# cc13x2_cc26x2 register map
File version: 2.1
CPU: CM4 r0p1, little endian, MPU, FPU, 3 interrupt priority bits
Registers are 32-bit, read-write, reset 0x0 unless marked. A register's access mark holds for its fields unless they carry their own. Offsets are from the block's base; [hi:lo] are bit positions; {n}, {i} and the like mark numbered series.

## CPU_SCS — Cortex-M's System Control Space (SCS)
Base 0xE000E000
0x04 ICTR ro reset 0x1 — Interrupt Control Type ead this register to see the number of interrupt lines that the NVIC supports.
  [2:0] INTLINESNUM
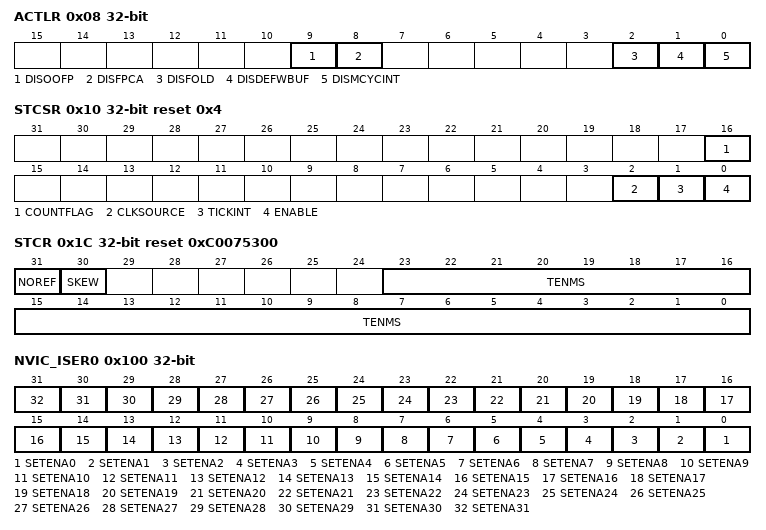
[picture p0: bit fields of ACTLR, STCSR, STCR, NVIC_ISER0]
0x08 ACTLR — Auxiliary Control his register is used to disable certain aspects of functionality within the processor
  [9] DISOOFP, [8] DISFPCA, [2] DISFOLD, [1] DISDEFWBUF, [0] DISMCYCINT
0x10 STCSR reset 0x4 — SysTick Control and Status his register enables the SysTick features and returns status flags related to SysTick.
  [16] COUNTFLAG, [2] CLKSOURCE, [1] TICKINT, [0] ENABLE
0x14 STRVR — SysTick Reload Value his register is used to specify the start value to load into the current value register STCVR.CURRENT when the counter reaches 0. It can be any value between 1 and 0x00FFFFFF. A start value of 0 is possible, but has no effect because the SysTick interrupt and STCSR.COUNTFLAG are activated when counting from 1 to 0.
  [23:0] RELOAD
0x18 STCVR — SysTick Current Value ead from this register returns the current value of SysTick counter. Writing to this register resets the SysTick counter (as well as STCSR.COUNTFLAG).
  [23:0] CURRENT
0x1C STCR ro reset 0xC0075300 — SysTick Calibration Value sed to enable software to scale to any required speed using divide and multiply.
  [31] NOREF, [30] SKEW, [23:0] TENMS
0x100 NVIC_ISER0 — Irq 0 to 31 Set Enable his register is used to enable interrupts and determine which interrupts are currently enabled.
  [n] SETENA{n} (n=0..31)
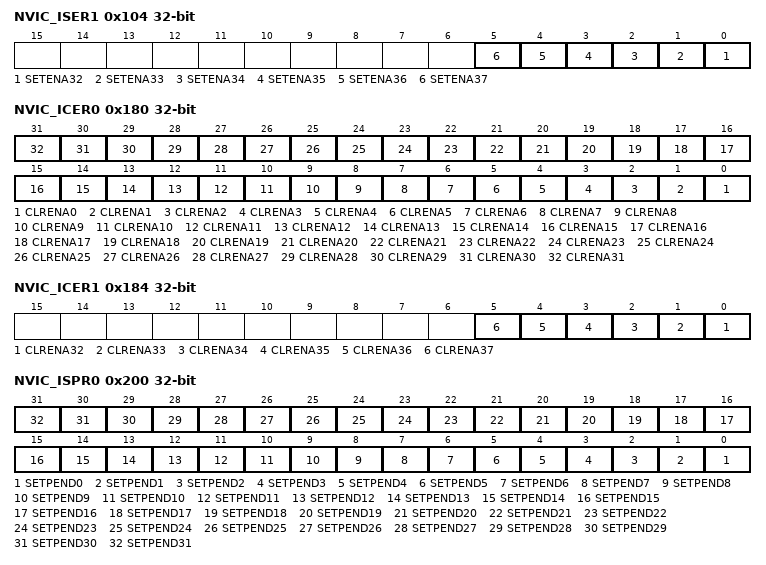
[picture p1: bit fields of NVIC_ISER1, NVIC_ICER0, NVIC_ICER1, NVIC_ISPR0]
0x104 NVIC_ISER1 — Irq 32 to 63 Set Enable his register is used to enable interrupts and determine which interrupts are currently enabled.
  [n-32] SETENA{n} (n=32..37)
0x180 NVIC_ICER0 — Irq 0 to 31 Clear Enable his register is used to disable interrupts and determine which interrupts are currently enabled.
  [n] CLRENA{n} (n=0..31)
0x184 NVIC_ICER1 — Irq 32 to 63 Clear Enable his register is used to disable interrupts and determine which interrupts are currently enabled.
  [n-32] CLRENA{n} (n=32..37)
0x200 NVIC_ISPR0 — Irq 0 to 31 Set Pending his register is used to force interrupts into the pending state and determine which interrupts are currently pending.
  [n] SETPEND{n} (n=0..31)
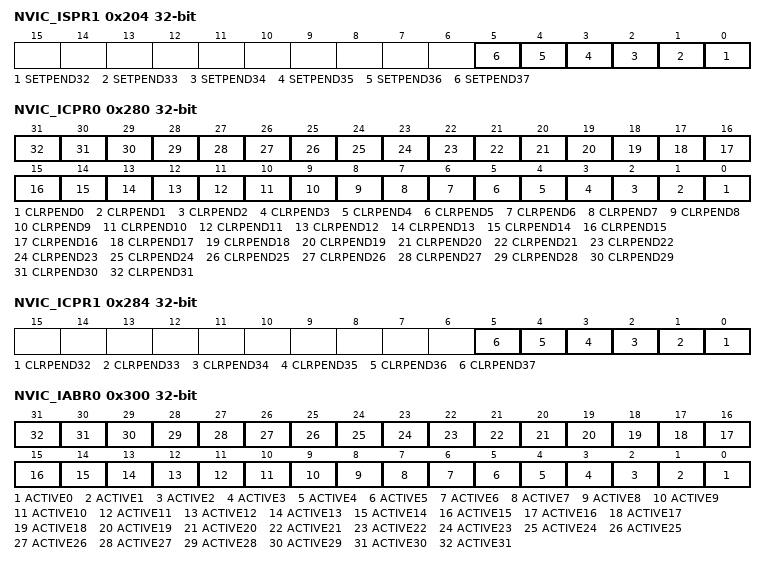
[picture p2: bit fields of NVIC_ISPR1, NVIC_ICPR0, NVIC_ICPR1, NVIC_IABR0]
0x204 NVIC_ISPR1 — Irq 32 to 63 Set Pending his register is used to force interrupts into the pending state and determine which interrupts are currently pending.
  [n-32] SETPEND{n} (n=32..37)
0x280 NVIC_ICPR0 — Irq 0 to 31 Clear Pending his register is used to clear pending interrupts and determine which interrupts are currently pending.
  [n] CLRPEND{n} (n=0..31)
0x284 NVIC_ICPR1 — Irq 32 to 63 Clear Pending his register is used to clear pending interrupts and determine which interrupts are currently pending.
  [n-32] CLRPEND{n} (n=32..37)
0x300 NVIC_IABR0 ro — Irq 0 to 31 Active Bit his register is used to determine which interrupts are active. Each flag in the register corresponds to one interrupt.
  [n] ACTIVE{n} (n=0..31)
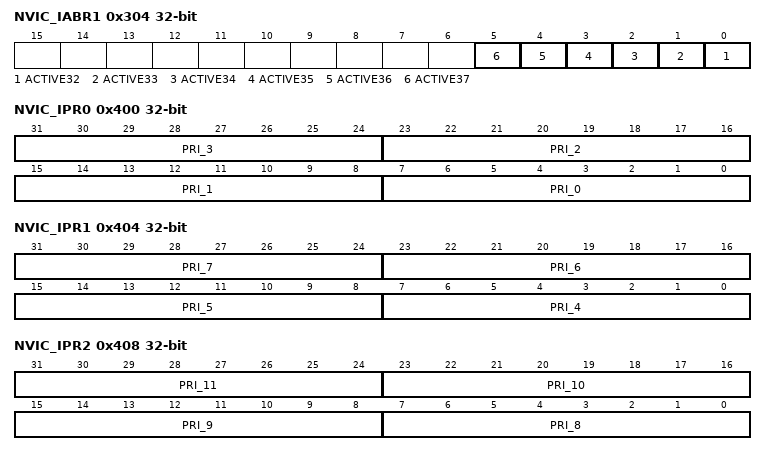
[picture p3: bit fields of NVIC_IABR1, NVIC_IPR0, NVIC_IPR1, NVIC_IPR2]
0x304 NVIC_IABR1 ro — Irq 32 to 63 Active Bit his register is used to determine which interrupts are active. Each flag in the register corresponds to one interrupt.
  [n-32] ACTIVE{n} (n=32..37)
0x400 NVIC_IPR0 — Irq 0 to 3 Priority his register is used to assign a priority from 0 to 255 to each of the available interrupts. 0 is the highest priority, and 255 is the lowest. The interpretation of the Interrupt Priority Registers changes based on the setting in AIRCR.PRIGROUP.
  [8n+7:8n] PRI_{n} (n=0..3)
0x404 NVIC_IPR1 — Irq 4 to 7 Priority his register is used to assign a priority from 0 to 255 to each of the available interrupts. 0 is the highest priority, and 255 is the lowest. The interpretation of the Interrupt Priority Registers changes based on the setting in AIRCR.PRIGROUP.
  [8n-25:8n-32] PRI_{n} (n=4..7)
0x408 NVIC_IPR2 — Irq 8 to 11 Priority his register is used to assign a priority from 0 to 255 to each of the available interrupts. 0 is the highest priority, and 255 is the lowest. The interpretation of the Interrupt Priority Registers changes based on the setting in AIRCR.PRIGROUP.
  [8n-57:8n-64] PRI_{n} (n=8..11)
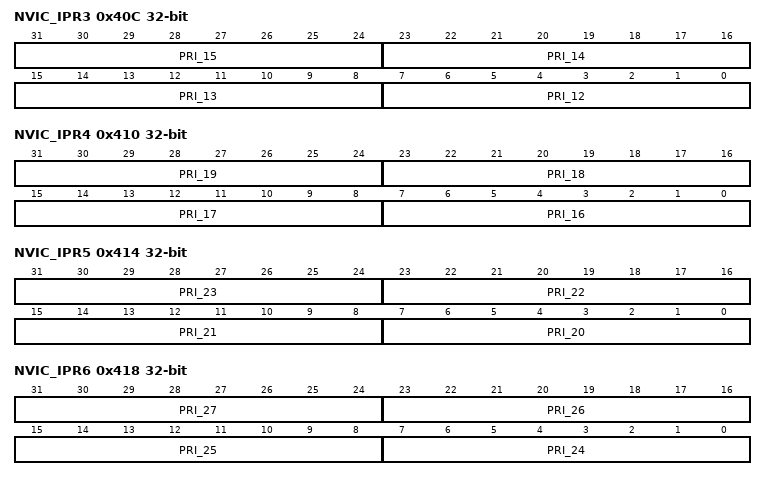
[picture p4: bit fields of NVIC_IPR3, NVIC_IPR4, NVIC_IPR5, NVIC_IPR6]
0x40C NVIC_IPR3 — Irq 12 to 15 Priority his register is used to assign a priority from 0 to 255 to each of the available interrupts. 0 is the highest priority, and 255 is the lowest. The interpretation of the Interrupt Priority Registers changes based on the setting in AIRCR.PRIGROUP.
  [8n-89:8n-96] PRI_{n} (n=12..15)
0x410 NVIC_IPR4 — Irq 16 to 19 Priority his register is used to assign a priority from 0 to 255 to each of the available interrupts. 0 is the highest priority, and 255 is the lowest. The interpretation of the Interrupt Priority Registers changes based on the setting in AIRCR.PRIGROUP.
  [8n-121:8n-128] PRI_{n} (n=16..19)
0x414 NVIC_IPR5 — Irq 20 to 23 Priority his register is used to assign a priority from 0 to 255 to each of the available interrupts. 0 is the highest priority, and 255 is the lowest. The interpretation of the Interrupt Priority Registers changes based on the setting in AIRCR.PRIGROUP.
  [8n-153:8n-160] PRI_{n} (n=20..23)
0x418 NVIC_IPR6 — Irq 24 to 27 Priority his register is used to assign a priority from 0 to 255 to each of the available interrupts. 0 is the highest priority, and 255 is the lowest. The interpretation of the Interrupt Priority Registers changes based on the setting in AIRCR.PRIGROUP.
  [8n-185:8n-192] PRI_{n} (n=24..27)
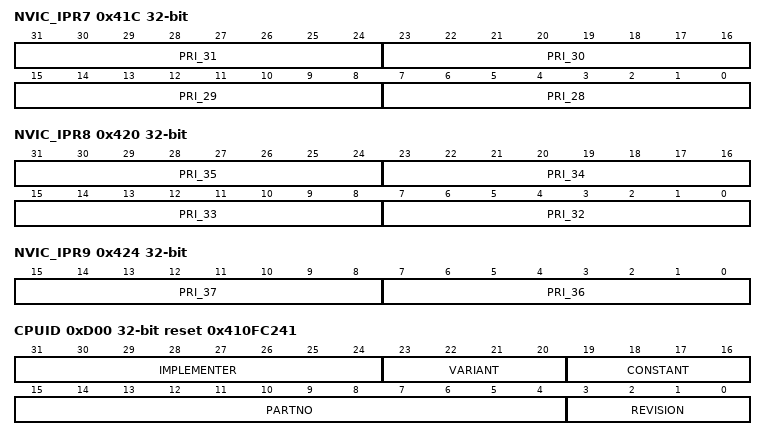
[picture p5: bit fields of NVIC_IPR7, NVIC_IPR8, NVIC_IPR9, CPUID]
0x41C NVIC_IPR7 — Irq 28 to 31 Priority his register is used to assign a priority from 0 to 255 to each of the available interrupts. 0 is the highest priority, and 255 is the lowest. The interpretation of the Interrupt Priority Registers changes based on the setting in AIRCR.PRIGROUP.
  [8n-217:8n-224] PRI_{n} (n=28..31)
0x420 NVIC_IPR8 — Irq 32 to 35 Priority his register is used to assign a priority from 0 to 255 to each of the available interrupts. 0 is the highest priority, and 255 is the lowest. The interpretation of the Interrupt Priority Registers changes based on the setting in AIRCR.PRIGROUP.
  [8n-249:8n-256] PRI_{n} (n=32..35)
0x424 NVIC_IPR9 — Irq 32 to 35 Priority his register is used to assign a priority from 0 to 255 to each of the available interrupts. 0 is the highest priority, and 255 is the lowest. The interpretation of the Interrupt Priority Registers changes based on the setting in AIRCR.PRIGROUP.
  [15:8] PRI_37, [7:0] PRI_36
0xD00 CPUID ro reset 0x410FC241 — CPUID Base his register determines the ID number of the processor core, the version number of the processor core and the implementation details of the processor core.
  [31:24] IMPLEMENTER, [23:20] VARIANT, [19:16] CONSTANT, [15:4] PARTNO, [3:0] REVISION
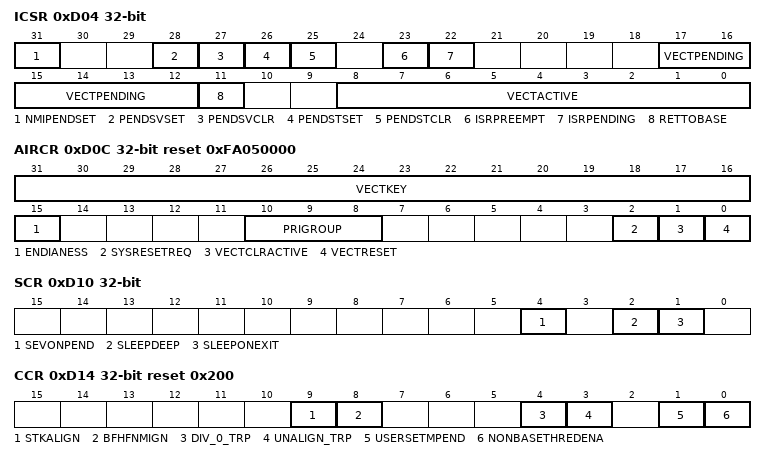
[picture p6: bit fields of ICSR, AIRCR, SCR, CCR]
0xD04 ICSR — Interrupt Control State his register is used to set a pending Non-Maskable Interrupt (NMI), set or clear a pending SVC, set or clear a pending SysTick, check for pending exceptions, check the vector number of the highest priority pended exception, and check the vector number of the active exception.
  [31] NMIPENDSET, [28] PENDSVSET, [27] PENDSVCLR, [26] PENDSTSET, [25] PENDSTCLR, [23] ISRPREEMPT, [22] ISRPENDING, [17:12] VECTPENDING, [11] RETTOBASE, [8:0] VECTACTIVE
0xD08 VTOR — Vector Table Offset his register is used to relocated the vector table base address. The vector table base offset determines the offset from the bottom of the memory map. The two most significant bits and the seven least significant bits of the vector table base offset must be 0. The portion of vector table base offset that is allowed to change is TBLOFF.
  [29:7] TBLOFF
0xD0C AIRCR reset 0xFA050000 — Application Interrupt/Reset Control his register is used to determine data endianness, clear all active state information for debug or to recover from a hard failure, execute a system reset, alter the priority grouping position (binary point).
  [31:16] VECTKEY, [15] ENDIANESS, [10:8] PRIGROUP, [2] SYSRESETREQ, [1] VECTCLRACTIVE, [0] VECTRESET
0xD10 SCR — System Control his register is used for power-management functions, i.e., signaling to the system when the processor can enter a low power state, controlling how the processor enters and exits low power states.
  [4] SEVONPEND, [2] SLEEPDEEP, [1] SLEEPONEXIT
0xD14 CCR reset 0x200 — Configuration Control his register is used to enable NMI, HardFault and FAULTMASK to ignore bus fault, trap divide by zero and unaligned accesses, enable user access to the Software Trigger Interrupt Register (STIR), control entry to Thread Mode.
  [9] STKALIGN, [8] BFHFNMIGN, [4] DIV_0_TRP, [3] UNALIGN_TRP, [1] USERSETMPEND, [0] NONBASETHREDENA
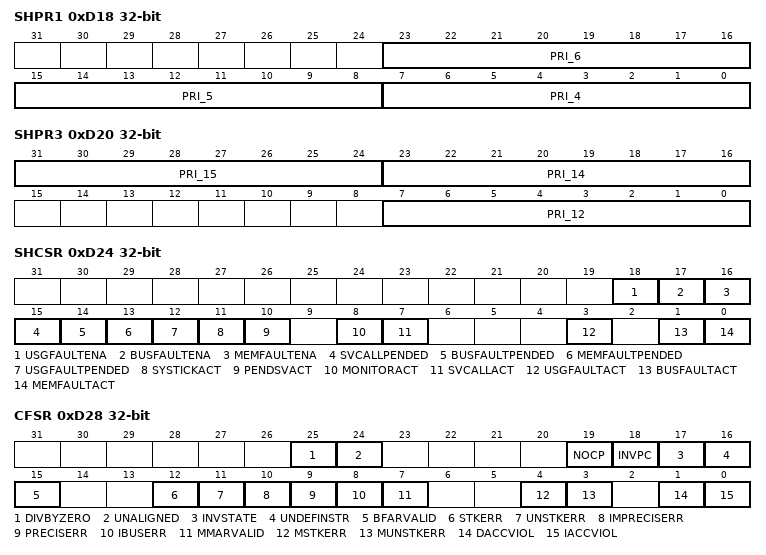
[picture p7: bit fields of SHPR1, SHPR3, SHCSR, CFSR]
0xD18 SHPR1 — System Handlers 4-7 Priority his register is used to prioritize the following system handlers: Memory manage, Bus fault, and Usage fault. System Handlers are a special class of exception handler that can have their priority set to any of the priority levels. Most can be masked on (enabled) or off (disabled). When disabled, the fault is always treated as a Hard Fault.
  [23:16] PRI_6, [15:8] PRI_5, [7:0] PRI_4
0xD1C SHPR2 — System Handlers 8-11 Priority his register is used to prioritize the SVC handler. System Handlers are a special class of exception handler that can have their priority set to any of the priority levels. Most can be masked on (enabled) or off (disabled). When disabled, the fault is always treated as a Hard Fault.
  [31:24] PRI_11
0xD20 SHPR3 — System Handlers 12-15 Priority his register is used to prioritize the following system handlers: SysTick, PendSV and Debug Monitor. System Handlers are a special class of exception handler that can have their priority set to any of the priority levels. Most can be masked on (enabled) or off (disabled). When disabled, the fault is always treated as a Hard Fault.
  [31:24] PRI_15, [23:16] PRI_14, [7:0] PRI_12
0xD24 SHCSR — System Handler Control and State his register is used to enable or disable the system handlers, determine the pending status of bus fault, mem manage fault, and SVC, determine the active status of the system handlers. If a fault condition occurs while its fault handler is disabled, the fault escalates to a Hard Fault.
  [18] USGFAULTENA, [17] BUSFAULTENA, [16] MEMFAULTENA, [15] SVCALLPENDED, [14] BUSFAULTPENDED, [13] MEMFAULTPENDED, [12] USGFAULTPENDED, [11] SYSTICKACT, [10] PENDSVACT, [8] MONITORACT, [7] SVCALLACT, [3] USGFAULTACT, [1] BUSFAULTACT, [0] MEMFAULTACT
0xD28 CFSR — Configurable Fault Status his register is used to obtain information about local faults. These registers include three subsections: The first byte is Memory Manage Fault Status Register (MMFSR). The second byte is Bus Fault Status Register (BFSR). The higher half-word is Usage Fault Status Register (UFSR). The flags in these registers indicate the causes of local faults. Multiple flags can be set if more than one fault occurs. These register are read/write-clear. This means that they can be read normally, but writing a 1 to any bit clears that bit. he CFSR is byte accessible. CFSR or its subregisters can be accessed as follows: he following accesses are possible to the CFSR register: access the complete register with a word access to 0xE000ED28. access the MMFSR with a byte access to 0xE000ED28 access the MMFSR and BFSR with a halfword access to 0xE000ED28 access the BFSR with a byte access to 0xE000ED29 access the UFSR with a halfword access to 0xE000ED2A.
  [25] DIVBYZERO, [24] UNALIGNED, [19] NOCP, [18] INVPC, [17] INVSTATE, [16] UNDEFINSTR, [15] BFARVALID, [12] STKERR, [11] UNSTKERR, [10] IMPRECISERR, [9] PRECISERR, [8] IBUSERR, [7] MMARVALID, [4] MSTKERR, [3] MUNSTKERR, [1] DACCVIOL, [0] IACCVIOL
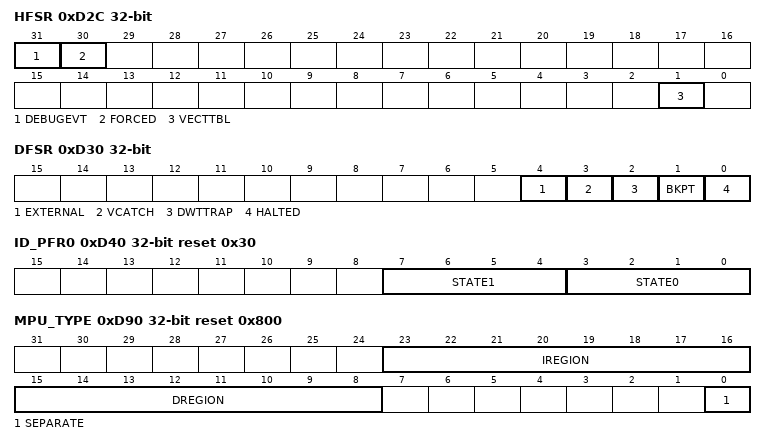
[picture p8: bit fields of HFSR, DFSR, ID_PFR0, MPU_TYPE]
0xD2C HFSR — Hard Fault Status his register is used to obtain information about events that activate the Hard Fault handler. This register is a write-clear register. This means that writing a 1 to a bit clears that bit.
  [31] DEBUGEVT write-1-clears, [30] FORCED write-1-clears, [1] VECTTBL write-1-clears
0xD30 DFSR — Debug Fault Status his register is used to monitor external debug requests, vector catches, data watchpoint match, BKPT instruction execution, halt requests. Multiple flags in the Debug Fault Status Register can be set when multiple fault conditions occur. The register is read/write clear. This means that it can be read normally. Writing a 1 to a bit clears that bit. Note that these bits are not set unless the event is caught. This means that it causes a stop of some sort. If halting debug is enabled, these events stop the processor into debug. If debug is disabled and the debug monitor is enabled, then this becomes a debug monitor handler call, if priority permits. If debug and the monitor are both disabled, some of these events are Hard Faults, and some are ignored.
  [4] EXTERNAL, [3] VCATCH, [2] DWTTRAP, [1] BKPT, [0] HALTED
0xD34 MMFAR — Mem Manage Fault Address his register is used to read the address of the location that caused a Memory Manage Fault.
  [31:0] ADDRESS
0xD38 BFAR — Bus Fault Address his register is used to read the address of the location that generated a Bus Fault.
  [31:0] ADDRESS
0xD3C AFSR — Auxiliary Fault Status his register is used to determine additional system fault information to software. Single-cycle high level on an auxiliary faults is latched as one. The bit can only be cleared by writing a one to the corresponding bit. Auxiliary fault inputs to the CPU are tied to 0.
  [31:0] IMPDEF
0xD40 ID_PFR0 ro reset 0x30 — Processor Feature 0
  [7:4] STATE1, [3:0] STATE0
0xD44 ID_PFR1 ro reset 0x200 — Processor Feature 1
  [11:8] MICROCONTROLLER_PROGRAMMERS_MODEL
0xD48 ID_DFR0 ro reset 0x100000 — Debug Feature 0 his register provides a high level view of the debug system. Further details are provided in the debug infrastructure itself.
  [23:20] MICROCONTROLLER_DEBUG_MODEL
0xD4C ID_AFR0 ro — Auxiliary Feature 0 his register provides some freedom for implementation defined features to be registered. Not used in Cortex-M.
0xD50 ID_MMFR0 ro reset 0x100030 — Memory Model Feature 0 eneral information on the memory model and memory management support.
0xD54 ID_MMFR1 ro — Memory Model Feature 1 eneral information on the memory model and memory management support.
0xD58 ID_MMFR2 ro reset 0x1000000 — Memory Model Feature 2 eneral information on the memory model and memory management support.
  [24] WAIT_FOR_INTERRUPT_STALLING
0xD5C ID_MMFR3 ro — Memory Model Feature 3 eneral information on the memory model and memory management support.
0xD60 ID_ISAR0 ro reset 0x1141110 — ISA Feature 0 nformation on the instruction set attributes register
0xD64 ID_ISAR1 ro reset 0x2112000 — ISA Feature 1 nformation on the instruction set attributes register
0xD68 ID_ISAR2 ro reset 0x21232231 — ISA Feature 2 nformation on the instruction set attributes register
0xD6C ID_ISAR3 ro reset 0x1111131 — ISA Feature 3 nformation on the instruction set attributes register
0xD70 ID_ISAR4 ro reset 0x1310102 — ISA Feature 4 nformation on the instruction set attributes register
0xD88 CPACR — Coprocessor Access Control his register specifies the access privileges for coprocessors.
0xD90 MPU_TYPE ro reset 0x800 — MPU Type his register indicates many regions the MPU supports.
  [23:16] IREGION, [15:8] DREGION, [0] SEPARATE
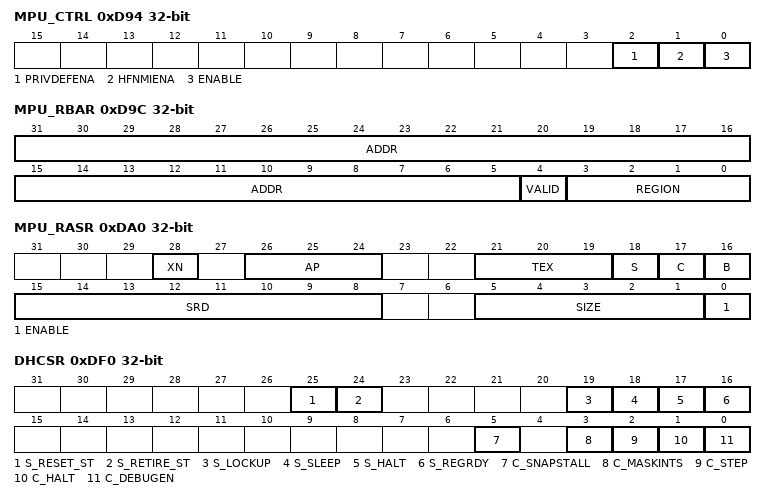
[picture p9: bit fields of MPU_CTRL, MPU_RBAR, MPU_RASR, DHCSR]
0xD94 MPU_CTRL — MPU Control his register is used to enable the MPU, enable the default memory map (background region), and enable the MPU when in Hard Fault, Non-maskable Interrupt (NMI), and FAULTMASK escalated handlers. When the MPU is enabled, at least one region of the memory map must be enabled for the MPU to function unless the PRIVDEFENA bit is set. If the PRIVDEFENA bit is set and no regions are enabled, then only privileged code can operate. When the MPU is disabled, the default address map is used, as if no MPU is present. When the MPU is enabled, only the system partition and vector table loads are always accessible. Other areas are accessible based on regions and whether PRIVDEFENA is enabled. Unless HFNMIENA is set, the MPU is not enabled when the exception priority is -1 or -2. These priorities are only possible when in Hard fault, NMI, or when FAULTMASK is enabled. The HFNMIENA bit enables the MPU when operating with these two priorities.
  [2] PRIVDEFENA, [1] HFNMIENA, [0] ENABLE
0xD98 MPU_RNR — MPU Region Number his register is used to select which protection region is accessed. The following write to MPU_RASR or MPU_RBAR configures the characteristics of the protection region that is selected by this register.
  [7:0] REGION
0xD9C MPU_RBAR — MPU Region Base Address his register writes the base address of a region. It also contains a REGION field that can be used to override MPU_RNR.REGION, if the VALID bit is set. This register sets the base for the region. It is aligned by the size. So, a 64-KB sized region must be aligned on a multiple of 64KB, for example, 0x00010000 or 0x00020000. The region always reads back as the current MPU region number. VALID always reads back as 0. Writing VALID = 1 and REGION = n changes the region number to n. This is a short-hand way to write the MPU_RNR. This register is unpredictable if accessed other than as a word.
  [31:5] ADDR, [4] VALID, [3:0] REGION
0xDA0 MPU_RASR — MPU Region Attribute and Size his register controls the MPU access permissions. The register is made up of two part registers, each of halfword size. These can be accessed using the halfword size, or they can both be simultaneously accessed using a word operation. The sub-region disable bits are not supported for region sizes of 32 bytes, 64 bytes, and 128 bytes. When these region sizes are used, the subregion disable bits must be programmed as 0.
  [28] XN, [26:24] AP, [21:19] TEX, [18] S, [17] C, [16] B, [15:8] SRD, [5:1] SIZE, [0] ENABLE
{0xD9C+8i} MPU_RBAR_A{i} (i=1..3) — MPU Alias {i} Region Base Address lias for MPU_RBAR
{0xDA0+8i} MPU_RASR_A{i} (i=1..3) — MPU Alias {i} Region Attribute and Size lias for MPU_RASR
0xDF0 DHCSR — Debug Halting Control and Status he purpose of this register is to provide status information about the state of the processor, enable core debug, halt and step the processor. For writes, 0xA05F must be written to higher half-word of this register, otherwise the write operation is ignored and no bits are written into the register. If not enabled for Halting mode, C_DEBUGEN = 1, all other fields are disabled. This register is not reset on a core reset. It is reset by a power-on reset. However, C_HALT always clears on a core reset. To halt on a reset, the following bits must be enabled: DEMCR.VC_CORERESET and C_DEBUGEN. Note that writes to this register in any size other than word are unpredictable. It is acceptable to read in any size, and it can be used to avoid or intentionally change a sticky bit. ehavior of the system when writing to this register while CPU is halted (i.e. C_DEBUGEN = 1 and S_HALT= 1): _HALT=0, C_STEP=0, C_MASKINTS=0 Exit Debug state and start instruction execution. Exceptions activate according to the exception configuration rules. _HALT=0, C_STEP=0, C_MASKINTS=1 Exit Debug state and start instruction execution. PendSV, SysTick and external configurable interrupts are disabled, otherwise exceptions activate according to standard configuration rules. _HALT=0, C_STEP=1, C_MASKINTS=0 Exit Debug state, step an instruction and halt. Exceptions activate according to the exception configuration rules. _HALT=0, C_STEP=1, C_MASKINTS=1 Exit Debug state, step an instruction and halt. PendSV, SysTick and external configurable interrupts are disabled, otherwise exceptions activate according to standard configuration rules. _HALT=1, C_STEP=x, C_MASKINTS=x Remain in Debug state
  [25] S_RESET_ST, [24] S_RETIRE_ST, [19] S_LOCKUP, [18] S_SLEEP, [17] S_HALT, [16] S_REGRDY, [5] C_SNAPSTALL, [3] C_MASKINTS, [2] C_STEP, [1] C_HALT, [0] C_DEBUGEN
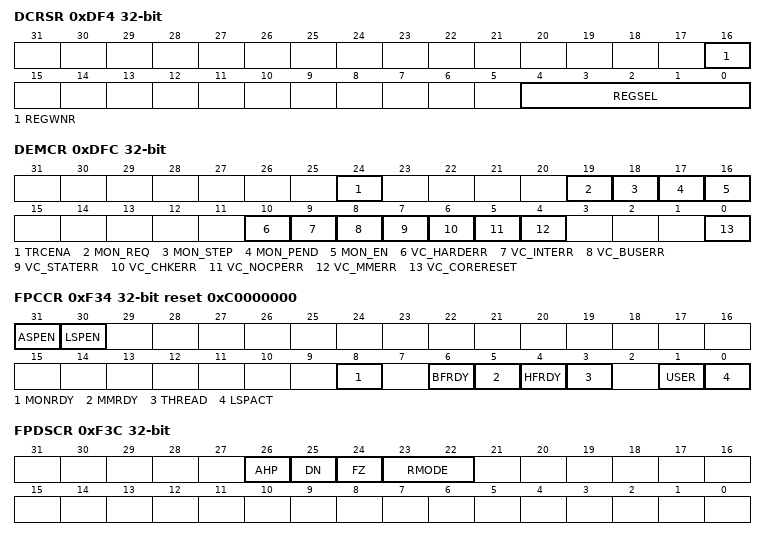
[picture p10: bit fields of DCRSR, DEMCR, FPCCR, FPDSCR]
0xDF4 DCRSR wo — Deubg Core Register Selector he purpose of this register is to select the processor register to transfer data to or from. This write-only register generates a handshake to the core to transfer data to or from Debug Core Register Data Register and the selected register. Until this core transaction is complete, DHCSR.S_REGRDY is 0. Note that writes to this register in any size but word are Unpredictable. ote that PSR registers are fully accessible this way, whereas some read as 0 when using MRS instructions. Note that all bits can be written, but some combinations cause a fault when execution is resumed.
  [16] REGWNR, [4:0] REGSEL
0xDF8 DCRDR — Debug Core Register Data
0xDFC DEMCR — Debug Exception and Monitor Control he purpose of this register is vector catching and debug monitor control. This register manages exception behavior under debug. Vector catching is only available to halting debug. The upper halfword is for monitor controls and the lower halfword is for halting exception support. This register is not reset on a system reset. This register is reset by a power-on reset. The fields MON_EN, MON_PEND, MON_STEP and MON_REQ are always cleared on a core reset. The debug monitor is enabled by software in the reset handler or later, or by the **AHB-AP** port. Vector catching is semi-synchronous. When a matching event is seen, a Halt is requested. Because the processor can only halt on an instruction boundary, it must wait until the next instruction boundary. As a result, it stops on the first instruction of the exception handler. However, two special cases exist when a vector catch has triggered: 1. If a fault is taken during a vector read or stack push error the halt occurs on the corresponding fault handler for the vector error or stack push. 2. If a late arriving interrupt detected during a vector read or stack push error it is not taken. That is, an implementation that supports the late arrival optimization must suppress it in this case.
  [24] TRCENA, [19] MON_REQ, [18] MON_STEP, [17] MON_PEND, [16] MON_EN, [10] VC_HARDERR, [9] VC_INTERR, [8] VC_BUSERR, [7] VC_STATERR, [6] VC_CHKERR, [5] VC_NOCPERR, [4] VC_MMERR, [0] VC_CORERESET
0xF00 STIR wo — Software Trigger Interrupt
  [8:0] INTID
0xF34 FPCCR reset 0xC0000000 — Floating Point Context Control his register holds control data for the floating-point unit. Accessible only by privileged software.
  [31] ASPEN, [30] LSPEN, [8] MONRDY, [6] BFRDY, [5] MMRDY, [4] HFRDY, [3] THREAD, [1] USER, [0] LSPACT
0xF38 FPCAR — Floating-Point Context Address his register holds the location of the unpopulated floating-point register space allocated on an exception stack frame.
  [31:2] ADDRESS
0xF3C FPDSCR — Floating Point Default Status Control his register holds the default values for the floating-point status control data that the processor assigns to the FPSCR when it creates a new floating-point context. Accessible only by privileged software.
  [26] AHP, [25] DN, [24] FZ, [23:22] RMODE
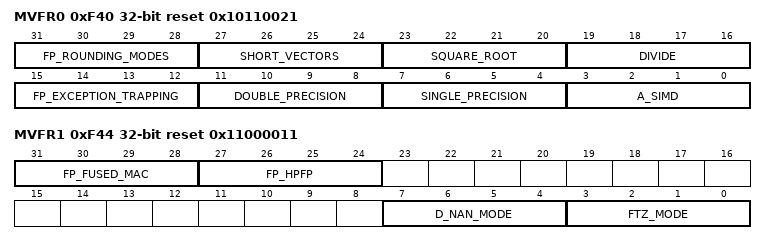
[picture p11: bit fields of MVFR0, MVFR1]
0xF40 MVFR0 ro reset 0x10110021 — Media and FP Feature 0 escribes the features provided by the Floating-point extension.
  [31:28] FP_ROUNDING_MODES, [27:24] SHORT_VECTORS, [23:20] SQUARE_ROOT, [19:16] DIVIDE, [15:12] FP_EXCEPTION_TRAPPING, [11:8] DOUBLE_PRECISION, [7:4] SINGLE_PRECISION, [3:0] A_SIMD
0xF44 MVFR1 ro reset 0x11000011 — Media and FP Feature 1 escribes the features provided by the Floating-point extension.
  [31:28] FP_FUSED_MAC, [27:24] FP_HPFP, [7:4] D_NAN_MODE, [3:0] FTZ_MODE
